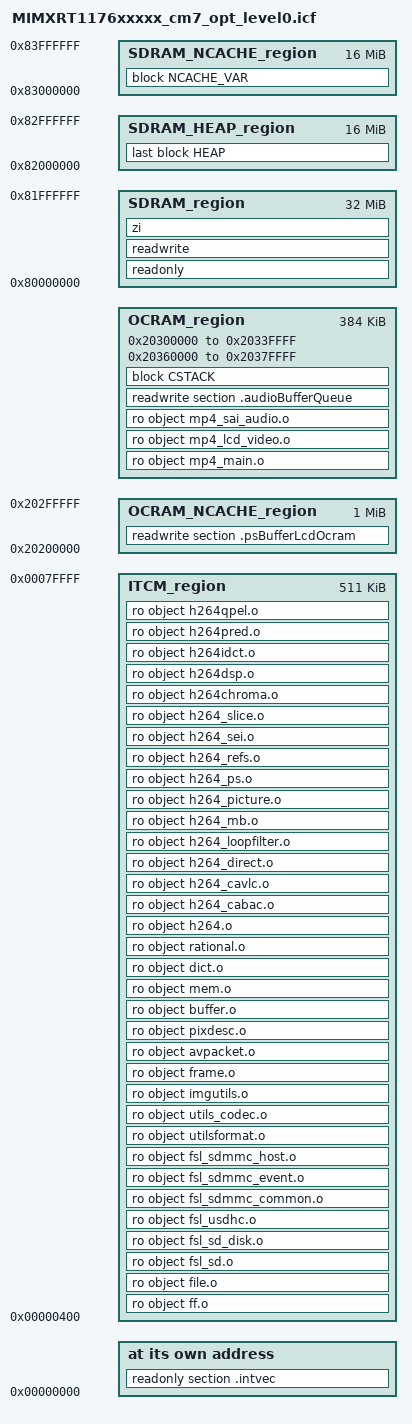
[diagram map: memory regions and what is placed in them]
/*
** ###################################################################
**     Processors:          MIMXRT1176AVM8A_cm7
**                          MIMXRT1176CVM8A_cm7
**                          MIMXRT1176DVMAA_cm7
**
**     Compiler:            IAR ANSI C/C++ Compiler for ARM
**     Reference manual:    IMXRT1170RM_initial_draft, 02/2018
**     Version:             rev. 0.1, 2018-03-05
**     Build:               b190819
**
**     Abstract:
**         Linker file for the IAR ANSI C/C++ Compiler for ARM
**
**     Copyright 2016 Freescale Semiconductor, Inc.
**     Copyright 2016-2019 NXP
**     All rights reserved.
**
**     SPDX-License-Identifier: BSD-3-Clause
**
**     http:                 www.nxp.com
**     mail:                 support@nxp.com
**
** ###################################################################
*/

define symbol m_itcm_interrupts_start = 0x00000000;
define symbol m_itcm_interrupts_end   = 0x000003FF;

define symbol m_itcm_start            = 0x00000400;
define symbol m_itcm_end              = 0x0007FFFF;

//define symbol m_dtcm_start            = 0x20000000;
//define symbol m_dtcm_end              = 0x2003FFFF;

define symbol m_ocram0_start           = 0x20200000;
define symbol m_ocram0_end             = 0x202FFFFF;

define symbol m_ocram1_start           = 0x20300000;
define symbol m_ocram1_end             = 0x2033FFFF;

define symbol m_ocram2_start           = 0x20360000;
define symbol m_ocram2_end             = 0x2037FFFF;

define symbol m_sdram_start           = 0x80000000;
define symbol m_sdram_end             = 0x82FFFFFF;

define symbol m_sdram_ncache_start    = 0x83000000;
define symbol m_sdram_ncache_end      = 0x83FFFFFF;

/* Sizes */
if (isdefinedsymbol(__stack_size__)) {
  define symbol __size_cstack__        = __stack_size__;
} else {
  define symbol __size_cstack__        = 0x8000;
}

if (isdefinedsymbol(__heap_size__)) {
  define symbol __size_heap__          = __heap_size__;
} else {
  define symbol __size_heap__          = 0x1000000;
}

define exported symbol __NCACHE_REGION_START   = m_sdram_ncache_start;
define exported symbol __NCACHE_REGION_SIZE    = m_sdram_ncache_end - m_sdram_ncache_start + 1;

define exported symbol __VECTOR_TABLE  = m_itcm_interrupts_start;
define exported symbol __VECTOR_RAM    = m_itcm_interrupts_start;
define exported symbol __RAM_VECTOR_TABLE_SIZE = 0x0;

define memory mem with size = 4G;
define region ITCM_region         = mem:[from m_itcm_start to m_itcm_end];
define region OCRAM_NCACHE_region = mem:[from m_ocram0_start to m_ocram0_end];
define region OCRAM_region        = mem:[from m_ocram1_start to m_ocram1_end]
                                  | mem:[from m_ocram2_start to m_ocram2_end];
define region SDRAM_region        = mem:[from m_sdram_start to m_sdram_end-__size_heap__];
define region SDRAM_HEAP_region   = mem:[from m_sdram_end-__size_heap__+1 to m_sdram_end];
define region SDRAM_NCACHE_region = mem:[from m_sdram_ncache_start to m_sdram_ncache_end];

define block CSTACK    with alignment = 8, size = __size_cstack__   { };
define block HEAP      with alignment = 8, size = __size_heap__     { };
//define block RW        { readwrite };
//define block ZI        { zi };
define block NCACHE_VAR with size = 0xb00000 , alignment = 0x100000  { section NonCacheable , section NonCacheable.init };

initialize by copy { readwrite, section .textrw };
do not initialize  { section .noinit };

place at address mem: m_itcm_interrupts_start     { readonly section .intvec };

place in OCRAM_NCACHE_region                      { readwrite section .psBufferLcdOcram };

place in OCRAM_region                             {
////////////////////////////////////////////////////////////////////////////////////////
//    Module                ro code  ro data     rw data
//    ------                -------  -------     -------
//    mp4_lcd_video.o         1 072      137   4 096 070
//    mp4_main.o              2 324      741      76 649
//    mp4_sai_audio.o         1 116      288         313
////////////////////////////////////////////////////////////////////////////////////////

                                                    ro object mp4_main.o,
                                                    ro object mp4_lcd_video.o,
                                                    ro object mp4_sai_audio.o,

                                                    readwrite section .audioBufferQueue,

                                                  };

place in ITCM_region                              {
////////////////////////////////////////////////////////////////////////////////////////
//    Module                ro code  ro data     rw data
//    ------                -------  -------     -------
//    ff.o                    5 404       28          15
//    file.o                    344      250         656
//    fsl_sd.o                6 124      356
//    fsl_sd_disk.o             216                  208
//    fsl_sdmmc_common.o        972      128         512
//    fsl_sdmmc_event.o         288                   12
//    fsl_sdmmc_host.o        1 132      168          85
//    fsl_usdhc.o             3 932      744          20
////////////////////////////////////////////////////////////////////////////////////////

                                                    ro object ff.o,
                                                    ro object file.o,
                                                    ro object fsl_sd.o,
                                                    ro object fsl_sd_disk.o,
                                                    ro object fsl_usdhc.o,
                                                    ro object fsl_sdmmc_common.o,
                                                    ro object fsl_sdmmc_event.o,
                                                    ro object fsl_sdmmc_host.o,


////////////////////////////////////////////////////////////////////////////////////////
//    Module                ro code  ro data     rw data
//    ------                -------  -------     -------
//    avpacket.o              1 876      216
//    frame.o                 2 416      100
//    imgutils.o              1 512      408
//    utils_codec.o          14 736    4 326          32
//    utilsformat.o          25 200    4 772
//    pixdesc.o                 476   53 611         200
//    buffer.o                  908
//    mem.o                     734      126           4
//    dict.o                    720        9
//    rational.o              1 080       16
////////////////////////////////////////////////////////////////////////////////////////

                                                    ro object utilsformat.o,
                                                    ro object utils_codec.o,
                                                    ro object imgutils.o,
                                                    ro object frame.o,
                                                    ro object avpacket.o,
                                                    ro object pixdesc.o,
                                                    ro object buffer.o,
                                                    ro object mem.o,
                                                    ro object dict.o,
                                                    ro object rational.o,


////////////////////////////////////////////////////////////////////////////////////////
//    Module                ro code  ro data     rw data
//    ------                -------  -------     -------
//    h264.o                 12 684    2 086         105
//    h264_cabac.o           18 404    9 304
//    h264_cavlc.o           15 752    2 848      75 828
//    h264_direct.o           6 102      264
//    h264_loopfilter.o       9 556    1 000
//    h264_mb.o              24 820       68
//    h264_picture.o            820      184
//    h264_ps.o               5 172    2 364
//    h264_refs.o             7 116    1 538
//    h264_sei.o              3 704      908
//    h264_slice.o           18 016    3 428
//    h264chroma.o            8 072
//    h264dsp.o              18 732      116
//    h264idct.o             12 718       82
//    h264pred.o             99 432      116
//    h264qpel.o             90 408
////////////////////////////////////////////////////////////////////////////////////////

                                                    ro object h264.o,
                                                    ro object h264_cabac.o,
                                                    ro object h264_cavlc.o,
                                                    ro object h264_direct.o,
                                                    ro object h264_loopfilter.o,
                                                    ro object h264_mb.o,
                                                    ro object h264_picture.o,
                                                    ro object h264_ps.o,
                                                    ro object h264_refs.o,
                                                    ro object h264_sei.o,
                                                    ro object h264_slice.o,
                                                    ro object h264chroma.o,
                                                    ro object h264dsp.o,
                                                    ro object h264idct.o,
                                                    ro object h264pred.o,
                                                    ro object h264qpel.o,

                                                    //rw object h264.o,
                                                    //rw object h264_cavlc.o

                                                  };

//initialize by copy { rw object h264.o,
//                     rw object h264_cavlc.o,
//                   };

place in SDRAM_region                             { readonly };
place in SDRAM_region                             { readwrite, zi };
place in OCRAM_region                             { block CSTACK };
place in SDRAM_HEAP_region                        { last block HEAP };
place in SDRAM_NCACHE_region                      { block NCACHE_VAR };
